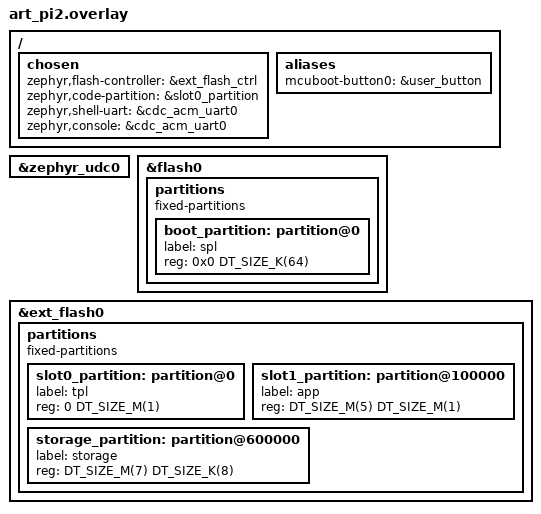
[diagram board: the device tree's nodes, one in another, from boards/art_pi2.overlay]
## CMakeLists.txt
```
# SPDX-License-Identifier: Apache-2.0

cmake_minimum_required(VERSION 3.20.0)

find_package(Zephyr REQUIRED HINTS $ENV{ZEPHYR_BASE})
project(tpl)

# ========================================
# TPL 固件头配置
# ========================================
target_compile_definitions(app PRIVATE
    FW_MAGIC_VALUE=FW_MAGIC_TPL
    FW_LOAD_ADDR=0x70000000
    FW_VERSION_VALUE=0x00010000     # v1.0.0
)

# ========================================
# 源文件
# ========================================
target_sources(app PRIVATE
    src/main.c
    src/fastboot_ops.c
    src/menu.c
    src/update_spl.c
    src/update_tpl.c
    src/update_app.c
    src/flash_helper.c
    ../common/ymodem.c
    ../common/firmware_loader.c
    ../common/fw_header.c
)

# ========================================
# 包含路径
# ========================================
zephyr_include_directories(app PRIVATE_HEADER ../common)

# ========================================
# 固件头链接脚本
# ========================================
# SORT_KEY "#fw_header" 确保固件头在 rom_start_address 之后、fill_with_zeros 之前
# ASCII 排序: "!" < "#fw_header" < "$" < "0x0" < "0x0vectors"
# 这样固件头位于地址 0x0-0x7F，填充到 0x400，向量表在 0x400
zephyr_linker_sources(ROM_START SORT_KEY "#fw_header" ../linker/fw_header.ld)

# ========================================
# 编译后处理：修正固件头 + 打印摘要
# 使用 add_custom_target + add_dependencies 确保在 zephyr_final 之后执行
# ========================================
set(FW_PATCH_SCRIPT "${CMAKE_SOURCE_DIR}/../tools/fw_patch.py")
set(FW_SUMMARY_SCRIPT "${CMAKE_SOURCE_DIR}/../tools/fw_summary.py")
set(ZEPHYR_BIN "${CMAKE_BINARY_DIR}/zephyr/zephyr.bin")

add_custom_target(tpl_patch_fw ALL
    COMMAND ${CMAKE_COMMAND} -E echo ""
    COMMAND ${CMAKE_COMMAND} -E echo "========================================"
    COMMAND ${CMAKE_COMMAND} -E echo "  Patching TPL firmware header..."
    COMMAND ${CMAKE_COMMAND} -E echo "========================================"
    COMMAND python3 ${FW_PATCH_SCRIPT} --vector-offset 0x400 ${ZEPHYR_BIN}
    COMMAND ${CMAKE_COMMAND} -E echo ""
    COMMAND python3 ${FW_SUMMARY_SCRIPT} ${ZEPHYR_BIN}
    COMMENT "Patching TPL firmware header and printing summary"
)

# 依赖 zephyr_final 目标（在 Zephyr 子目录中定义）
# CMake 允许跨目录的 add_dependencies
add_dependencies(tpl_patch_fw zephyr_final)
```

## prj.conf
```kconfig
CONFIG_MAIN_STACK_SIZE=4096
CONFIG_HEAP_MEM_POOL_SIZE=65536

CONFIG_STDOUT_CONSOLE=y

CONFIG_SERIAL=y
CONFIG_UART_STM32=y
CONFIG_UART_CONSOLE=y
CONFIG_GPIO=y
CONFIG_FLASH=y
CONFIG_FLASH_PAGE_LAYOUT=y
CONFIG_FLASH_STM32_XSPI=y
CONFIG_STM32_MEMMAP=y
CONFIG_USE_DT_CODE_PARTITION=y
CONFIG_FLASH_BASE_ADDRESS=0x70000000

CONFIG_LOG=y

# 使用内存缓冲日志，避免串口输出延迟影响 USB 枚举时序
CONFIG_LOG_MODE_DEFERRED=y
CONFIG_LOG_PROCESS_THREAD=y
CONFIG_LOG_PROCESS_THREAD_STACK_SIZE=1024
CONFIG_LOG_BUFFER_SIZE=65536
CONFIG_LOG_PRINTK=y
CONFIG_SHELL=y
CONFIG_CRC=y
CONFIG_REBOOT=y
CONFIG_BOOTLOADER_MCUBOOT=y
CONFIG_USB_DEVICE_STACK_NEXT=y
CONFIG_USBD_CDC_ACM_CLASS=y
CONFIG_USBD_FASTBOOT_CLASS=y
CONFIG_USBD_FASTBOOT_DOWNLOAD_BUF_SIZE=32768
CONFIG_USBD_FASTBOOTD=y
# CONFIG_UDC_STM32_CLOCK_CHECK is not set

# Increase UDC buffer pool to prevent buffer exhaustion
CONFIG_UDC_BUF_COUNT=32
CONFIG_UDC_BUF_POOL_SIZE=2048

# Increase UDC STM32 message queue size to prevent message loss
# during interrupt bursts (e.g., TXFE storm on short packet echo)
CONFIG_UDC_STM32_MAX_QMESSAGES=32

# Enable CDC ACM dedicated buffer pool
CONFIG_USBD_CDC_ACM_BUF_POOL=y

# Increase USB device core message queue size (default 10)
# Prevents event loss when multiple UDC events are queued rapidly
CONFIG_USBD_MAX_UDC_MSG=20

CONFIG_USBD_COMPOSITE_DEVICE=y

CONFIG_USBD_SHELL=y
```

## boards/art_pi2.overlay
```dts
/*
 * Copyright (c) 2024
 *
 * SPDX-License-Identifier: Apache-2.0
 */

/ {
    chosen {
        zephyr,flash-controller = &ext_flash_ctrl;
        zephyr,code-partition = &slot0_partition;
        zephyr,shell-uart = &cdc_acm_uart0;
        zephyr,console = &cdc_acm_uart0;
    };

    aliases {
        mcuboot-button0 = &user_button;
    };
};

&zephyr_udc0 {
    status = "okay";
};

&flash0 {
    partitions {
        compatible = "fixed-partitions";
        #address-cells = <1>;
        #size-cells = <1>;

        boot_partition: partition@0 {
            label = "spl";
            reg = <0x0 DT_SIZE_K(64)>;
        };
    };
};

&ext_flash0 {
    partitions {
        compatible = "fixed-partitions";
        #address-cells = <1>;
        #size-cells = <1>;

        /* 删除基础设备树中的 storage_partition */
        /delete-node/ partition@0;

        slot0_partition: partition@0 {
            label = "tpl";
            reg = <0 DT_SIZE_M(1)>;
        };

        slot1_partition: partition@100000 {
            label = "app";
            reg = <DT_SIZE_M(5) DT_SIZE_M(1)>;
        };

        storage_partition: partition@600000 {
            label = "storage";
            reg = <DT_SIZE_M(7) DT_SIZE_K(8)>;
        };
    };
};
```

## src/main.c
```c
/*
 * Copyright (c) 2024
 * SPDX-License-Identifier: Apache-2.0
 */

#include <zephyr/kernel.h>
#include <zephyr/sys/printk.h>
#include <zephyr/device.h>
#include <zephyr/devicetree.h>
#include <zephyr/drivers/gpio.h>
#include <cmsis_core.h>
#include "flash_helper.h"

#define RED_LED_NODE DT_NODELABEL(red_led)
#define BLUE_LED_NODE DT_NODELABEL(blue_led)
static const struct gpio_dt_spec red_led =
	GPIO_DT_SPEC_GET_OR(RED_LED_NODE, gpios, {0});
static const struct gpio_dt_spec blue_led =
	GPIO_DT_SPEC_GET_OR(BLUE_LED_NODE, gpios, {0});

int main(void)
{
	SCB_EnableICache();
	SCB_EnableDCache();

	if (device_is_ready(red_led.port)) {
		gpio_pin_configure_dt(&red_led, GPIO_OUTPUT);
	}
	if (device_is_ready(blue_led.port)) {
		gpio_pin_configure_dt(&blue_led, GPIO_OUTPUT);
	}

	flash_internal_init();
	flash_external_init();

	printk("TPL initialized\n");

	while (1) {
		k_sleep(K_MSEC(100));
	}
	return 0;
}
```

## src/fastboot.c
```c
/*
 * Copyright (c) 2024
 *
 * SPDX-License-Identifier: Apache-2.0
 */

/**
 * @file fastboot.c
 * @brief Fastboot protocol implementation for TPL bootloader
 */

#include "fastboot.h"
#include "flash_helper.h"
#include "firmware_loader.h"
#include "firmware_header.h"

#include <zephyr/kernel.h>
#include <zephyr/device.h>
#include <zephyr/usb/usbd.h>
#include <zephyr/logging/log.h>
#include <zephyr/sys/reboot.h>
#include <zephyr/sys/printk.h>
#include <string.h>
#include <stdlib.h>
#include <stdio.h>

LOG_MODULE_REGISTER(fastboot, CONFIG_LOG_DEFAULT_LEVEL);

/* ============================================================
 * USB Device Context & Descriptors
 * ============================================================ */

USBD_DEVICE_DEFINE(fastboot_usbd,
		   DEVICE_DT_GET(DT_NODELABEL(zephyr_udc0)),
		   FASTBOOT_VID, FASTBOOT_PID);

USBD_DESC_LANG_DEFINE(fastboot_lang);
USBD_DESC_MANUFACTURER_DEFINE(fastboot_mfr, "ART-Pi2");
USBD_DESC_PRODUCT_DEFINE(fastboot_product, "ART-Pi2 TPL Fastboot");

// USBD_DESC_CONFIG_DEFINE(fastboot_fs_cfg_desc, "Fastboot FS Config");
USBD_DESC_CONFIG_DEFINE(fastboot_hs_cfg_desc, "Fastboot HS Config");
// USBD_CONFIGURATION_DEFINE(fastboot_fs_config, 0, 250, &fastboot_fs_cfg_desc);
USBD_CONFIGURATION_DEFINE(fastboot_hs_config, 0, 250, &fastboot_hs_cfg_desc);

/* ============================================================
 * Fastboot Descriptors (must be in RAM, not flash)
 * ============================================================ */

/*
 * Descriptor template - used to init writable copies in RAM.
 * These are const and can stay in flash.
 */
#define FS_BULK_MPS USB_CONTROL_EP_MPS
#define HS_BULK_MPS 512

// static const struct usb_if_descriptor fastboot_fs_iface_tpl = {
// 	.bLength = sizeof(struct usb_if_descriptor),
// 	.bDescriptorType = USB_DESC_INTERFACE,
// 	.bInterfaceNumber = 0,
// 	.bAlternateSetting = 0,
// 	.bNumEndpoints = 2,
// 	.bInterfaceClass = FASTBOOT_IFACE_CLASS,
// 	.bInterfaceSubClass = FASTBOOT_IFACE_SUBCLASS,
// 	.bInterfaceProtocol = FASTBOOT_IFACE_PROTOCOL,
// 	.iInterface = 0,
// };

// static const struct usb_ep_descriptor fastboot_fs_bulk_out_tpl = {
// 	.bLength = sizeof(struct usb_ep_descriptor),
// 	.bDescriptorType = USB_DESC_ENDPOINT,
// 	.bEndpointAddress = FASTBOOT_BULK_OUT_EP,
// 	.bmAttributes = USB_EP_TYPE_BULK,
// 	.wMaxPacketSize = sys_cpu_to_le16(FS_BULK_MPS),
// 	.bInterval = 0x00,
// };

// static const struct usb_ep_descriptor fastboot_fs_bulk_in_tpl = {
// 	.bLength = sizeof(struct usb_ep_descriptor),
// 	.bDescriptorType = USB_DESC_ENDPOINT,
// 	.bEndpointAddress = FASTBOOT_BULK_IN_EP,
// 	.bmAttributes = USB_EP_TYPE_BULK,
// 	.wMaxPacketSize = sys_cpu_to_le16(FS_BULK_MPS),
// 	.bInterval = 0x00,
// };

static const struct usb_if_descriptor fastboot_hs_iface_tpl = {
	.bLength = sizeof(struct usb_if_descriptor),
	.bDescriptorType = USB_DESC_INTERFACE,
	.bInterfaceNumber = 0,
	.bAlternateSetting = 0,
	.bNumEndpoints = 2,
	.bInterfaceClass = FASTBOOT_IFACE_CLASS,
	.bInterfaceSubClass = FASTBOOT_IFACE_SUBCLASS,
	.bInterfaceProtocol = FASTBOOT_IFACE_PROTOCOL,
	.iInterface = 0,
};

static const struct usb_ep_descriptor fastboot_hs_bulk_out_tpl = {
	.bLength = sizeof(struct usb_ep_descriptor),
	.bDescriptorType = USB_DESC_ENDPOINT,
	.bEndpointAddress = FASTBOOT_BULK_OUT_EP,
	.bmAttributes = USB_EP_TYPE_BULK,
	.wMaxPacketSize = sys_cpu_to_le16(HS_BULK_MPS),
	.bInterval = 0x00,
};

static const struct usb_ep_descriptor fastboot_hs_bulk_in_tpl = {
	.bLength = sizeof(struct usb_ep_descriptor),
	.bDescriptorType = USB_DESC_ENDPOINT,
	.bEndpointAddress = FASTBOOT_BULK_IN_EP,
	.bmAttributes = USB_EP_TYPE_BULK,
	.wMaxPacketSize = sys_cpu_to_le16(HS_BULK_MPS),
	.bInterval = 0x00,
};

/* RAM copies of descriptors (BSS, in SRAM, writable) */
// static struct {
// 	struct usb_if_descriptor iface;
// 	struct usb_ep_descriptor bulk_out;
// 	struct usb_ep_descriptor bulk_in;
// 	struct usb_desc_header *desc_array[4];
// } fastboot_fs_desc_ram;

static struct {
	struct usb_if_descriptor iface;
	struct usb_ep_descriptor bulk_out;
	struct usb_ep_descriptor bulk_in;
	struct usb_desc_header *desc_array[4];
} fastboot_hs_desc_ram;

/* Pointers for get_desc() to return */
static struct usb_desc_header **fastboot_fs_desc;
static struct usb_desc_header **fastboot_hs_desc;

/* ============================================================
 * Fastboot Context & Class API
 * ============================================================ */

/* Static download buffer allocated from heap on demand */
static struct fastboot_ctx fb_ctx = {
	.state = FASTBOOT_STATE_OFFLINE,
	.download_buf = NULL,
};

static struct usbd_class_data *fb_c_data;

/* Forward declarations */
static void fastboot_process_data(struct usbd_class_data *c_data,
				  const uint8_t *data, size_t len);

/* Forward declarations */
static void fastboot_process_data(struct usbd_class_data *c_data,
				  const uint8_t *data, size_t len);
static void fastboot_init_desc(void);

static void *fastboot_get_desc(struct usbd_class_data *const c_data,
			       const enum usbd_speed speed)
{
	ARG_UNUSED(c_data);

	/* Ensure RAM descriptor copies are initialized before first use */
	fastboot_init_desc();

	if (speed == USBD_SPEED_HS) {
		return (void *)fastboot_hs_desc;
	}
	return (void *)fastboot_fs_desc;
}

static int fastboot_request(struct usbd_class_data *const c_data,
			    struct net_buf *buf, int err)
{
	struct usbd_context *ctx = usbd_class_get_ctx(c_data);

	if (err != 0) {
		printk("fastboot: bulk err %d\n", err);
		usbd_ep_buf_free(ctx, buf);
		return err;
	}

	if (buf->len > 0) {
		fastboot_process_data(c_data, buf->data, buf->len);
	}

	usbd_ep_buf_free(ctx, buf);

	/* Re-submit bulk OUT */
	{
		struct net_buf *new_buf = usbd_ep_buf_alloc(c_data,
					FASTBOOT_BULK_OUT_EP, 64);
		if (new_buf) {
			usbd_ep_enqueue(c_data, new_buf);
		}
	}

	return 0;
}

static void fastboot_enable(struct usbd_class_data *const c_data)
{
	struct net_buf *buf;

	printk("fastboot: enabled\n");
	fb_c_data = c_data;
	fb_ctx.state = FASTBOOT_STATE_IDLE;

	buf = usbd_ep_buf_alloc(c_data, FASTBOOT_BULK_OUT_EP, 64);
	if (buf) {
		usbd_ep_enqueue(c_data, buf);
	}
}

static void fastboot_disable(struct usbd_class_data *const c_data)
{
	printk("fastboot: disabled\n");
	fb_c_data = NULL;
	fb_ctx.state = FASTBOOT_STATE_OFFLINE;
	usbd_ep_dequeue(usbd_class_get_ctx(c_data), FASTBOOT_BULK_OUT_EP);
	usbd_ep_dequeue(usbd_class_get_ctx(c_data), FASTBOOT_BULK_IN_EP);
}

static void fastboot_init_desc(void)
{
	static bool initialized;

	if (initialized) {
		return;
	}

	// memcpy(&fastboot_fs_desc_ram.iface, &fastboot_fs_iface_tpl,
	//        sizeof(fastboot_fs_desc_ram.iface));
	// memcpy(&fastboot_fs_desc_ram.bulk_out, &fastboot_fs_bulk_out_tpl,
	//        sizeof(fastboot_fs_desc_ram.bulk_out));
	// memcpy(&fastboot_fs_desc_ram.bulk_in, &fastboot_fs_bulk_in_tpl,
	//        sizeof(fastboot_fs_desc_ram.bulk_in));
	// fastboot_fs_desc_ram.desc_array[0] = (struct usb_desc_header *)&fastboot_fs_desc_ram.iface;
	// fastboot_fs_desc_ram.desc_array[1] = (struct usb_desc_header *)&fastboot_fs_desc_ram.bulk_out;
	// fastboot_fs_desc_ram.desc_array[2] = (struct usb_desc_header *)&fastboot_fs_desc_ram.bulk_in;
	// fastboot_fs_desc_ram.desc_array[3] = NULL;
	// fastboot_fs_desc = fastboot_fs_desc_ram.desc_array;

	memcpy(&fastboot_hs_desc_ram.iface, &fastboot_hs_iface_tpl,
	       sizeof(fastboot_hs_desc_ram.iface));
	memcpy(&fastboot_hs_desc_ram.bulk_out, &fastboot_hs_bulk_out_tpl,
	       sizeof(fastboot_hs_desc_ram.bulk_out));
	memcpy(&fastboot_hs_desc_ram.bulk_in, &fastboot_hs_bulk_in_tpl,
	       sizeof(fastboot_hs_desc_ram.bulk_in));
	fastboot_hs_desc_ram.desc_array[0] = (struct usb_desc_header *)&fastboot_hs_desc_ram.iface;
	fastboot_hs_desc_ram.desc_array[1] = (struct usb_desc_header *)&fastboot_hs_desc_ram.bulk_out;
	fastboot_hs_desc_ram.desc_array[2] = (struct usb_desc_header *)&fastboot_hs_desc_ram.bulk_in;
	fastboot_hs_desc_ram.desc_array[3] = NULL;
	fastboot_hs_desc = fastboot_hs_desc_ram.desc_array;

	initialized = true;
}

static int fastboot_init_class(struct usbd_class_data *const c_data)
{
	ARG_UNUSED(c_data);
	memset(&fb_ctx, 0, sizeof(fb_ctx));
	fb_ctx.state = FASTBOOT_STATE_OFFLINE;
	printk("fastboot: class init\n");
	return 0;
}

static const struct usbd_class_api fastboot_class_api = {
	.get_desc    = fastboot_get_desc,
	.request     = fastboot_request,
	.enable      = fastboot_enable,
	.disable     = fastboot_disable,
	.init        = fastboot_init_class,
};

USBD_DEFINE_CLASS(fastboot_class, &fastboot_class_api, &fb_ctx, NULL);

/* ============================================================
 * Fastboot Response Helpers
 * ============================================================ */

static int fastboot_send(struct usbd_class_data *c_data,
			 const char *data, size_t len)
{
	struct net_buf *buf;
	if (!c_data) return -ENODEV;
	buf = usbd_ep_buf_alloc(c_data, FASTBOOT_BULK_IN_EP, len);
	if (!buf) return -ENOMEM;
	net_buf_add_mem(buf, data, len);
	return usbd_ep_enqueue(c_data, buf);
}

#define fastboot_okay(c)    fastboot_send((c), "OKAY", 4)
#define fastboot_fail(c,m)  do { \
	char _b[64]; int _n = snprintf(_b, sizeof(_b), "FAIL%s", (m)); \
	fastboot_send((c), _b, _n); } while(0)

/* ============================================================
 * Partition Table
 * ============================================================ */

struct fastboot_part {
	const char *name;
	uint32_t addr;
	uint32_t size;
	uint32_t magic;
	bool internal;
};

static const struct fastboot_part parts[] = {
	{"spl", FLASH_BASE_ADDR, SPL_FLASH_SIZE, FW_MAGIC_SPL, true},
	{"tpl", EXT_FLASH_SLOT0_ADDR, EXT_FLASH_SLOT0_SIZE, FW_MAGIC_TPL, false},
	{"app", EXT_FLASH_SLOT1_ADDR, EXT_FLASH_SLOT1_SIZE, FW_MAGIC_APP, false},
};

static const struct fastboot_part *find_part(const char *name)
{
	for (size_t i = 0; i < ARRAY_SIZE(parts); i++) {
		if (strcmp(parts[i].name, name) == 0) return &parts[i];
	}
	return NULL;
}

/* ============================================================
 * Command Handlers
 * ============================================================ */

static void cmd_getvar(struct usbd_class_data *c, const char *arg)
{
	char buf[64];

	if (strcmp(arg, "version") == 0) {
		fastboot_send(c, "OKAY0.4", 7);
	} else if (strcmp(arg, "board") == 0) {
		fastboot_send(c, "OKAYart-pi2", 12);
	} else if (strcmp(arg, "serial") == 0) {
		fastboot_send(c, "OKAY000000000000", 16);
	} else if (strcmp(arg, "max-download-size") == 0) {
		snprintf(buf, sizeof(buf), "OKAY0x%08x", FASTBOOT_DOWNLOAD_BUF);
		fastboot_send(c, buf, strlen(buf));
	} else if (strcmp(arg, "all") == 0) {
		fastboot_send(c, "INFOversion: 0.4", 16);
		fastboot_send(c, "INFOboard: art-pi2", 17);
		fastboot_send(c, "INFOserial: 000000000000", 22);
		fastboot_send(c, "INFOmax-download-size: 0x8000", 29);
		fastboot_okay(c);
	} else if (strncmp(arg, "partition-size:", 15) == 0) {
		const struct fastboot_part *p = find_part(arg + 15);
		if (p) {
			snprintf(buf, sizeof(buf), "OKAY0x%08x", p->size);
			fastboot_send(c, buf, strlen(buf));
		} else {
			fastboot_fail(c, "no such partition");
		}
	} else if (strncmp(arg, "partition-type:", 15) == 0) {
		const struct fastboot_part *p = find_part(arg + 15);
		if (p) {
			fastboot_send(c, "OKAYraw", 7);
		} else {
			fastboot_fail(c, "no such partition");
		}
	} else {
		fastboot_okay(c);
	}
}

static void cmd_download(struct usbd_class_data *c, const char *arg)
{
	uint32_t size = (uint32_t)strtoul(arg, NULL, 16);

	if (size == 0 || size > FASTBOOT_DOWNLOAD_BUF) {
		fastboot_fail(c, "bad size");
		return;
	}

	if (!fb_ctx.download_buf) {
		fb_ctx.download_buf = k_malloc(FASTBOOT_DOWNLOAD_BUF);
		if (!fb_ctx.download_buf) {
			fastboot_fail(c, "oom");
			return;
		}
	}

	fb_ctx.download_size = size;
	fb_ctx.download_received = 0;
	fb_ctx.state = FASTBOOT_STATE_DOWNLOAD;

	char resp[16];
	snprintf(resp, sizeof(resp), "DATA%08x", size);
	fastboot_send(c, resp, strlen(resp));
}

static void cmd_flash(struct usbd_class_data *c, const char *arg)
{
	const struct fastboot_part *p;
	int rc;

	if (fb_ctx.state != FASTBOOT_STATE_DOWNLOADED) {
		fastboot_fail(c, "no firmware downloaded");
		return;
	}

	p = find_part(arg);
	if (!p) {
		fastboot_fail(c, "no such partition");
		return;
	}

	if (fb_ctx.download_received < sizeof(struct firmware_header)) {
		fastboot_fail(c, "firmware too small");
		return;
	}

	/* Verify header */
	struct firmware_header *hdr = (struct firmware_header *)fb_ctx.download_buf;
	if (firmware_header_verify(hdr, p->magic) != FW_LOADER_SUCCESS) {
		fastboot_fail(c, "bad firmware header");
		return;
	}

	printk("fastboot: erasing %s...\n", p->name);
	if (p->internal) {
		rc = flash_internal_erase(p->addr, p->size);
	} else {
		rc = flash_external_erase(p->addr, p->size);
	}
	if (rc) { fastboot_fail(c, "erase failed"); return; }

	printk("fastboot: writing %s...\n", p->name);
	{
		uint32_t off = 0;
		uint32_t left = fb_ctx.download_received;
		while (left > 0) {
			uint32_t chunk = MIN(left, 256);
			if (p->internal) {
				rc = flash_internal_write(p->addr + off,
					fb_ctx.download_buf + off, chunk);
			} else {
				rc = flash_external_write(p->addr + off,
					fb_ctx.download_buf + off, chunk);
			}
			if (rc) break;
			off += chunk;
			left -= chunk;
		}
	}
	if (rc) { fastboot_fail(c, "write failed"); return; }

	/* TPL: set update request flag */
	if (strcmp(arg, "tpl") == 0) {
		flash_set_update_request(UPDATE_REQ_TPL);
	}

	fb_ctx.state = FASTBOOT_STATE_IDLE;
	k_free(fb_ctx.download_buf);
	fb_ctx.download_buf = NULL;

	fastboot_okay(c);
}

static void cmd_erase(struct usbd_class_data *c, const char *arg)
{
	const struct fastboot_part *p = find_part(arg);
	if (!p) { fastboot_fail(c, "no such partition"); return; }

	int rc;
	if (p->internal) {
		rc = flash_internal_erase(p->addr, p->size);
	} else {
		rc = flash_external_erase(p->addr, p->size);
	}

	if (rc) { fastboot_fail(c, "erase failed"); }
	else    { fastboot_okay(c); }
}

/* ============================================================
 * Command Dispatcher
 * ============================================================ */

static void handle_cmd(struct usbd_class_data *c, const char *cmd)
{
	printk("fastboot: cmd '%s'\n", cmd);

	if (strncmp(cmd, "getvar:", 7) == 0)
		cmd_getvar(c, cmd + 7);
	else if (strncmp(cmd, "download:", 9) == 0)
		cmd_download(c, cmd + 9);
	else if (strncmp(cmd, "flash:", 6) == 0)
		cmd_flash(c, cmd + 6);
	else if (strncmp(cmd, "erase:", 6) == 0)
		cmd_erase(c, cmd + 6);
	else if (strcmp(cmd, "reboot") == 0) {
		fastboot_okay(c);
		k_sleep(K_MSEC(100));
		sys_reboot(SYS_REBOOT_COLD);
	} else if (strcmp(cmd, "continue") == 0)
		fastboot_okay(c);
	else
		fastboot_fail(c, "unknown command");
}

/* ============================================================
 * Data Processor
 * ============================================================ */

static void fastboot_process_data(struct usbd_class_data *c_data,
				  const uint8_t *data, size_t len)
{
	switch (fb_ctx.state) {

	case FASTBOOT_STATE_IDLE: {
		char cmd[64];
		size_t n = MIN(len, sizeof(cmd) - 1);
		memcpy(cmd, data, n);
		cmd[n] = '\0';
		while (n > 0 && (cmd[n-1] == '\r' || cmd[n-1] == '\n'))
			cmd[--n] = '\0';
		if (n > 0) handle_cmd(c_data, cmd);
		break;
	}

	case FASTBOOT_STATE_DOWNLOAD: {
		uint32_t copy = MIN(len,
			fb_ctx.download_size - fb_ctx.download_received);
		if (copy > 0) {
			memcpy(fb_ctx.download_buf + fb_ctx.download_received,
			       data, copy);
			fb_ctx.download_received += copy;
		}
		if (fb_ctx.download_received >= fb_ctx.download_size) {
			fb_ctx.state = FASTBOOT_STATE_DOWNLOADED;
			fastboot_okay(c_data);
		}
		break;
	}

	default:
		fastboot_fail(c_data, "protocol error");
		fb_ctx.state = FASTBOOT_STATE_IDLE;
		break;
	}
}

/* ============================================================
 * VBUS Message Callback
 * ============================================================ */

static void fb_msg_cb(struct usbd_context *const ctx,
		      const struct usbd_msg *msg)
{
	switch (msg->type) {
	case USBD_MSG_VBUS_READY:
		printk("fastboot: VBUS ready\n");
		usbd_enable(ctx);
		break;
	case USBD_MSG_VBUS_REMOVED:
		printk("fastboot: VBUS removed\n");
		usbd_disable(ctx);
		break;
	default:
		break;
	}
}

/* ============================================================
 * Public API
 * ============================================================ */

int fastboot_init(void)
{
	struct usbd_context *uds_ctx = &fastboot_usbd;
	int err;

	printk("fastboot: init start\n");

	err = usbd_add_descriptor(uds_ctx, &fastboot_lang);
	if (err) { printk("fastboot: lang fail %d\n", err); return err; }

	err = usbd_add_descriptor(uds_ctx, &fastboot_mfr);
	if (err) { printk("fastboot: mfr fail %d\n", err); return err; }

	err = usbd_add_descriptor(uds_ctx, &fastboot_product);
	if (err) { printk("fastboot: product fail %d\n", err); return err; }

	err = usbd_msg_register_cb(uds_ctx, fb_msg_cb);
	if (err) { printk("fastboot: msg cb fail %d\n", err); return err; }

	// err = usbd_add_configuration(uds_ctx, USBD_SPEED_FS,
	// 			     &fastboot_fs_config);
	// if (err) { printk("fastboot: FS cfg fail %d\n", err); return err; }

	err = usbd_add_configuration(uds_ctx, USBD_SPEED_HS,
				     &fastboot_hs_config);
	if (err) { printk("fastboot: HS cfg fail %d\n", err); return err; }

	// err = usbd_register_class(uds_ctx, "fastboot_class",
	// 			  USBD_SPEED_FS, 1);
	// if (err) { printk("fastboot: FS reg fail %d\n", err); return err; }

	err = usbd_register_class(uds_ctx, "fastboot_class",
				  USBD_SPEED_HS, 1);
	if (err) { printk("fastboot: HS reg fail %d\n", err); return err; }

	err = usbd_init(uds_ctx);
	if (err) { printk("fastboot: init fail %d\n", err); return err; }

	if (usbd_can_detect_vbus(uds_ctx)) {
		printk("fastboot: VBUS detect enabled, waiting for cable\n");
	} else {
		printk("fastboot: no VBUS detect, enabling directly\n");
		err = usbd_enable(uds_ctx);
		if (err) { printk("fastboot: enable fail %d\n", err); return err; }
	}

	printk("fastboot: USB ready\n");
	return 0;
}

void fastboot_poll(void)
{
	/* USB is interrupt-driven, nothing to poll */
}
```

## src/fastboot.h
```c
/*
 * Copyright (c) 2024
 *
 * SPDX-License-Identifier: Apache-2.0
 */

#ifndef FASTBOOT_H
#define FASTBOOT_H

/**
 * @file fastboot.h
 * @brief Fastboot protocol implementation for TPL bootloader
 *
 * Implements the Android Fastboot protocol for firmware updates via USB.
 * Uses Zephyr's new USB device stack (USB_DEVICE_STACK_NEXT).
 */

#include <zephyr/kernel.h>
#include <zephyr/types.h>
#include <stdbool.h>
#include <stddef.h>
#include <stdint.h>

/* ============================================================
 * Fastboot USB Device Identification
 * ============================================================ */

#define FASTBOOT_VID             0x2FE3  /* Zephyr Project VID */
#define FASTBOOT_PID             0x1001  /* TPL Fastboot PID */

/* ============================================================
 * Fastboot USB Interface Descriptor Values
 * ============================================================ */

#define FASTBOOT_IFACE_CLASS      0xFF
#define FASTBOOT_IFACE_SUBCLASS   0x42
#define FASTBOOT_IFACE_PROTOCOL   0x03

/* ============================================================
 * USB Endpoint Assignments
 * ============================================================ */

#define FASTBOOT_BULK_OUT_EP      0x01   /* EP1 OUT (host to device) */
#define FASTBOOT_BULK_IN_EP       0x81   /* EP1 IN  (device to host) */

/* ============================================================
 * Protocol Constants
 * ============================================================ */

#define FASTBOOT_MAX_CMDBUF       64
#define FASTBOOT_MAX_RSPBUF       64

/*
 * Download buffer size: 32KB.
 * SRAM0 (zephyr,sram) = 456KB but BSS/data/text share this space.
 * TPL itself plus USB stack takes significant RAM.
 * Start small for testing; increase once USB enumeration is verified.
 */
#define FASTBOOT_DOWNLOAD_BUF     (32 * 1024)

/* Fastboot response prefixes */
#define FASTBOOT_RSP_OKAY         "OKAY"
#define FASTBOOT_RSP_FAIL         "FAIL"
#define FASTBOOT_RSP_DATA         "DATA"
#define FASTBOOT_RSP_INFO         "INFO"

/* ============================================================
 * Fastboot State Machine
 * ============================================================ */

enum fastboot_state {
	FASTBOOT_STATE_OFFLINE,      /* USB not yet enabled */
	FASTBOOT_STATE_IDLE,         /* Waiting for commands */
	FASTBOOT_STATE_DOWNLOAD,     /* Receiving firmware data */
	FASTBOOT_STATE_DOWNLOADED,   /* Firmware ready, waiting for flash/cmd */
	FASTBOOT_STATE_ERROR,        /* Error, need to recover */
};

/* ============================================================
 * Fastboot Context
 * ============================================================ */

struct fastboot_ctx {
	enum fastboot_state state;
	uint8_t *download_buf;
	uint32_t download_size;
	uint32_t download_received;
};

/* ============================================================
 * Public API
 * ============================================================ */

/**
 * @brief Initialize Fastboot USB device
 *
 * @return 0 on success, negative errno on failure
 */
int fastboot_init(void);

/**
 * @brief Fastboot poll function (for main loop)
 */
void fastboot_poll(void);

#endif /* FASTBOOT_H */
```

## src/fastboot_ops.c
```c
/*
 * Copyright (c) 2024
 *
 * SPDX-License-Identifier: Apache-2.0
 */

/**
 * @file fastboot_ops.c
 * @brief Fastboot Ops and partition registration (SYS_INIT)
 *
 * Runs before usbd_fastbootd init to register partitions and
 * flash operations before USB is initialized.
 */

#include <zephyr/init.h>
#include <zephyr/kernel.h>
#include <zephyr/devicetree.h>
#include <zephyr/usb/class/usbd_fastboot.h>

#include "flash_helper.h"
#include "firmware_header.h"

/* ============================================================
 * Partition Table (from DTS)
 * ============================================================ */

static const struct fastboot_part fb_parts[] = {
	FASTBOOT_PART_DEFINE(DT_NODELABEL(boot_partition),  FW_MAGIC_SPL, true),
	FASTBOOT_PART_DEFINE(DT_NODELABEL(slot0_partition), FW_MAGIC_TPL, false),
	FASTBOOT_PART_DEFINE(DT_NODELABEL(slot1_partition), FW_MAGIC_APP, false),
};

/* ============================================================
 * Ops
 * ============================================================ */

static int fb_flash_erase(uint32_t addr, uint32_t size)
{
	if (addr >= 0x08000000 && addr < 0x08100000) {
		return flash_internal_erase(addr, size);
	}
	return flash_external_erase(addr, size);
}

static int fb_flash_write(uint32_t addr, const uint8_t *data, uint32_t size)
{
	if (addr >= 0x08000000 && addr < 0x08100000) {
		return flash_internal_write(addr, data, size);
	}
	return flash_external_write(addr, data, size);
}

static int fb_firmware_verify(const uint8_t *data, uint32_t size,
			      uint32_t expected_magic)
{
	if (size < sizeof(struct firmware_header)) {
		return -EINVAL;
	}
	const struct firmware_header *hdr =
		(const struct firmware_header *)data;

	return (hdr->magic == expected_magic) ? 0 : -EINVAL;
}

static struct fastboot_ops fb_ops = {
	.flash_erase     = fb_flash_erase,
	.flash_write     = fb_flash_write,
	.firmware_verify = fb_firmware_verify,
};

/* ============================================================
 * SYS_INIT: runs before usbd_fastbootd
 * ============================================================ */

static int fastboot_ops_init(void)
{
	fastboot_register_partitions(fb_parts, ARRAY_SIZE(fb_parts));
	fastboot_register_ops(&fb_ops);
	return 0;
}

SYS_INIT(fastboot_ops_init, APPLICATION, CONFIG_APPLICATION_INIT_PRIORITY);
```

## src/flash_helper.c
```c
/*
 * Copyright (c) 2024
 *
 * SPDX-License-Identifier: Apache-2.0
 */

#include "flash_helper.h"
#include <zephyr/sys/printk.h>
#include <string.h>

/* Flash 设备指针 */
static const struct device *flash_internal_dev = NULL;
static const struct device *flash_external_dev = NULL;

/* CRC16 表 (多项式: 0x1021) */
static const uint16_t crc16_table[256] = {
    0x0000, 0x1021, 0x2042, 0x3063, 0x4084, 0x50A5, 0x60C6, 0x70E7,
    0x8108, 0x9129, 0xA14A, 0xB16B, 0xC18C, 0xD1AD, 0xE1CE, 0xF1EF,
    0x1231, 0x0210, 0x3273, 0x2252, 0x52B5, 0x4294, 0x72F7, 0x62D6,
    0x9339, 0x8318, 0xB37B, 0xA35A, 0xD3BD, 0xC39C, 0xF3FF, 0xE3DE,
    0x2462, 0x3443, 0x0420, 0x1401, 0x64E6, 0x74C7, 0x44A4, 0x5485,
    0xA56A, 0xB54B, 0x8528, 0x9509, 0xE5EE, 0xF5CF, 0xC5AC, 0xD58D,
    0x3653, 0x2672, 0x1611, 0x0630, 0x76D7, 0x66F6, 0x5695, 0x46B4,
    0xB75B, 0xA77A, 0x9719, 0x8738, 0xF7DF, 0xE7FE, 0xD79D, 0xC7BC,
    0x48C4, 0x58E5, 0x6886, 0x78A7, 0x0840, 0x1861, 0x2802, 0x3823,
    0xC9CC, 0xD9ED, 0xE98E, 0xF9AF, 0x8948, 0x9969, 0xA90A, 0xB92B,
    0x5AF5, 0x4AD4, 0x7AB7, 0x6A96, 0x1A71, 0x0A50, 0x3A33, 0x2A12,
    0xDBFD, 0xCBDC, 0xFBBF, 0xEB9E, 0x9B79, 0x8B58, 0xBB3B, 0xAB1A,
    0x6CA6, 0x7C87, 0x4CE4, 0x5CC5, 0x2C22, 0x3C03, 0x0C60, 0x1C41,
    0xEDAE, 0xFD8F, 0xCDEC, 0xDDCD, 0xAD2A, 0xBD0B, 0x8D68, 0x9D49,
    0x7E97, 0x6EB6, 0x5ED5, 0x4EF4, 0x3E13, 0x2E32, 0x1E51, 0x0E70,
    0xFF9F, 0xEFBE, 0xDFDD, 0xCFFC, 0xBF1B, 0xAF3A, 0x9F59, 0x8F78,
    0x9188, 0x81A9, 0xB1CA, 0xA1EB, 0xD10C, 0xC12D, 0xF14E, 0xE16F,
    0x1080, 0x00A1, 0x30C2, 0x20E3, 0x5004, 0x4025, 0x7046, 0x6067,
    0x83B9, 0x9398, 0xA3FB, 0xB3DA, 0xC33D, 0xD31C, 0xE37F, 0xF35E,
    0x02B1, 0x1290, 0x22F3, 0x32D2, 0x4235, 0x5214, 0x6277, 0x7256,
    0xB5EA, 0xA5CB, 0x95A8, 0x8589, 0xF56E, 0xE54F, 0xD52C, 0xC50D,
    0x34E2, 0x24C3, 0x14A0, 0x0481, 0x7466, 0x6447, 0x5424, 0x4405,
    0xA7DB, 0xB7FA, 0x8799, 0x97B8, 0xE75F, 0xF77E, 0xC71D, 0xD73C,
    0x26D3, 0x36F2, 0x0691, 0x16B0, 0x6657, 0x7676, 0x4615, 0x5634,
    0xD94C, 0xC96D, 0xF90E, 0xE92F, 0x99C8, 0x89E9, 0xB98A, 0xA9AB,
    0x5844, 0x4865, 0x7806, 0x6827, 0x18C0, 0x08E1, 0x3882, 0x28A3,
    0xCB7D, 0xDB5C, 0xEB3F, 0xFB1E, 0x8BF9, 0x9BD8, 0xABBB, 0xBB9A,
    0x4A75, 0x5A54, 0x6A37, 0x7A16, 0x0AF1, 0x1AD0, 0x2AB3, 0x3A92,
    0xFD2E, 0xED0F, 0xDD6C, 0xCD4D, 0xBDAA, 0xAD8B, 0x9DE8, 0x8DC9,
    0x7C26, 0x6C07, 0x5C64, 0x4C45, 0x3CA2, 0x2C83, 0x1CE0, 0x0CC1,
    0xEF1F, 0xFF3E, 0xCF5D, 0xDF7C, 0xAF9B, 0xBFBA, 0x8FD9, 0x9FF8,
    0x6E17, 0x7E36, 0x4E55, 0x5E74, 0x2E93, 0x3EB2, 0x0ED1, 0x1EF0
};

int flash_internal_init(void)
{
    flash_internal_dev = DEVICE_DT_GET(DT_NODELABEL(flash));

    if (!device_is_ready(flash_internal_dev)) {
        printk("Error: Internal flash device not ready\n");
        return FLASH_OP_ERROR;
    }

    return FLASH_OP_SUCCESS;
}

int flash_external_init(void)
{
    flash_external_dev = DEVICE_DT_GET(DT_NODELABEL(ext_flash_ctrl));

    if (!device_is_ready(flash_external_dev)) {
        printk("Error: External flash device not ready\n");
        return FLASH_OP_ERROR;
    }

    return FLASH_OP_SUCCESS;
}

int flash_internal_erase(uint32_t addr, size_t len)
{
    struct flash_pages_info page_info;
    off_t offset;
    int rc;

    if (flash_internal_dev == NULL) {
        if (flash_internal_init() != FLASH_OP_SUCCESS) {
            return FLASH_OP_ERROR;
        }
    }

    if (addr < FLASH_BASE_ADDR || (addr + len) > (FLASH_BASE_ADDR + SPL_FLASH_SIZE)) {
        printk("Error: Invalid internal flash address range\n");
        return FLASH_OP_ERROR;
    }

    offset = addr - FLASH_BASE_ADDR;

    rc = flash_get_page_info_by_offs(flash_internal_dev, offset, &page_info);
    if (rc != 0) {
        printk("Error: Failed to get page info\n");
        return FLASH_OP_ERROR;
    }

    rc = flash_erase(flash_internal_dev, page_info.start_offset, page_info.size);
    if (rc != 0) {
        printk("Error: Flash erase failed (rc=%d)\n", rc);
        return FLASH_OP_ERROR;
    }

    return FLASH_OP_SUCCESS;
}

int flash_internal_write(uint32_t addr, const uint8_t *data, size_t len)
{
    off_t offset;
    int rc;

    if (flash_internal_dev == NULL) {
        if (flash_internal_init() != FLASH_OP_SUCCESS) {
            return FLASH_OP_ERROR;
        }
    }

    if (addr < FLASH_BASE_ADDR || (addr + len) > (FLASH_BASE_ADDR + SPL_FLASH_SIZE)) {
        printk("Error: Invalid internal flash address range\n");
        return FLASH_OP_ERROR;
    }

    if ((addr & 0x3) != 0) {
        printk("Error: Flash write address must be 4-byte aligned\n");
        return FLASH_OP_ERROR;
    }

    offset = addr - FLASH_BASE_ADDR;

    rc = flash_write(flash_internal_dev, offset, data, len);
    if (rc != 0) {
        printk("Error: Flash write failed (rc=%d)\n", rc);
        return FLASH_OP_ERROR;
    }

    return FLASH_OP_SUCCESS;
}

int flash_internal_read(uint32_t addr, uint8_t *data, size_t len)
{
    off_t offset;
    int rc;

    if (flash_internal_dev == NULL) {
        if (flash_internal_init() != FLASH_OP_SUCCESS) {
            return FLASH_OP_ERROR;
        }
    }

    if (addr < FLASH_BASE_ADDR || (addr + len) > (FLASH_BASE_ADDR + SPL_FLASH_SIZE)) {
        printk("Error: Invalid internal flash address range\n");
        return FLASH_OP_ERROR;
    }

    offset = addr - FLASH_BASE_ADDR;

    rc = flash_read(flash_internal_dev, offset, data, len);
    if (rc != 0) {
        printk("Error: Flash read failed (rc=%d)\n", rc);
        return FLASH_OP_ERROR;
    }

    return FLASH_OP_SUCCESS;
}

int flash_external_erase(uint32_t addr, size_t len)
{
    struct flash_pages_info page_info;
    off_t offset;
    int rc;

    if (flash_external_dev == NULL) {
        if (flash_external_init() != FLASH_OP_SUCCESS) {
            return FLASH_OP_ERROR;
        }
    }

    offset = addr - EXT_FLASH_BASE_ADDR;

    rc = flash_get_page_info_by_offs(flash_external_dev, offset, &page_info);
    if (rc != 0) {
        printk("Error: Failed to get page info\n");
        return FLASH_OP_ERROR;
    }

    rc = flash_erase(flash_external_dev, page_info.start_offset, page_info.size);
    if (rc != 0) {
        printk("Error: External flash erase failed (rc=%d)\n", rc);
        return FLASH_OP_ERROR;
    }

    return FLASH_OP_SUCCESS;
}

int flash_external_write(uint32_t addr, const uint8_t *data, size_t len)
{
    off_t offset;
    int rc;

    if (flash_external_dev == NULL) {
        if (flash_external_init() != FLASH_OP_SUCCESS) {
            return FLASH_OP_ERROR;
        }
    }

    if ((addr & 0x3) != 0) {
        printk("Error: Flash write address must be 4-byte aligned\n");
        return FLASH_OP_ERROR;
    }

    offset = addr - EXT_FLASH_BASE_ADDR;

    rc = flash_write(flash_external_dev, offset, data, len);
    if (rc != 0) {
        printk("Error: External flash write failed (rc=%d)\n", rc);
        return FLASH_OP_ERROR;
    }

    return FLASH_OP_SUCCESS;
}

int flash_external_read(uint32_t addr, uint8_t *data, size_t len)
{
    off_t offset;
    int rc;

    if (flash_external_dev == NULL) {
        if (flash_external_init() != FLASH_OP_SUCCESS) {
            return FLASH_OP_ERROR;
        }
    }

    offset = addr - EXT_FLASH_BASE_ADDR;

    rc = flash_read(flash_external_dev, offset, data, len);
    if (rc != 0) {
        printk("Error: External flash read failed (rc=%d)\n", rc);
        return FLASH_OP_ERROR;
    }

    return FLASH_OP_SUCCESS;
}

bool flash_verify_magic(uint32_t addr, uint32_t magic)
{
    uint32_t *ptr = (uint32_t *)addr;

    if ((addr & 0x3) != 0) {
        return false;
    }

    return (*ptr == magic);
}

uint16_t flash_calc_crc16(const uint8_t *data, size_t len)
{
    uint16_t crc = 0xFFFF;

    while (len--) {
        crc = (crc << 8) ^ crc16_table[((crc >> 8) ^ *data++) & 0xFF];
    }

    return crc;
}

bool flash_verify_crc(uint32_t addr, size_t len, uint16_t expected_crc)
{
    uint16_t calc_crc;
    const uint8_t *data = (const uint8_t *)addr;

    calc_crc = flash_calc_crc16(data, len);

    return (calc_crc == expected_crc);
}

int flash_copy_ext_to_int(uint32_t dst_addr, uint32_t src_addr, size_t len)
{
    uint8_t *src_ptr;
    int rc;

    /* 源地址在外部 Flash Memory Map 区域，可以直接读取 */
    src_ptr = (uint8_t *)src_addr;

    /* 按页写入内部 Flash */
    size_t offset = 0;
    while (offset < len) {
        size_t write_len = (len - offset > 256) ? 256 : (len - offset);

        rc = flash_internal_write(dst_addr + offset, src_ptr + offset, write_len);
        if (rc != 0) {
            printk("Error: Copy ext to int failed at offset 0x%x\n", offset);
            return FLASH_OP_ERROR;
        }

        offset += write_len;
    }

    return FLASH_OP_SUCCESS;
}

int flash_copy_ext_to_ext(uint32_t dst_addr, uint32_t src_addr, size_t len)
{
    uint8_t *src_ptr;
    int rc;

    /* 源地址在外部 Flash Memory Map 区域，可以直接读取 */
    src_ptr = (uint8_t *)src_addr;

    /* 按页写入外部 Flash */
    size_t offset = 0;
    while (offset < len) {
        size_t write_len = (len - offset > 256) ? 256 : (len - offset);

        rc = flash_external_write(dst_addr + offset, src_ptr + offset, write_len);
        if (rc != 0) {
            printk("Error: Copy ext to ext failed at offset 0x%x\n", offset);
            return FLASH_OP_ERROR;
        }

        offset += write_len;
    }

    return FLASH_OP_SUCCESS;
}

int flash_storage_write(uint32_t offset, const uint8_t *data, size_t len)
{
    uint32_t addr = EXT_FLASH_STORAGE_ADDR + offset;

    if (offset + len > EXT_FLASH_STORAGE_SIZE) {
        printk("Error: Storage write out of bounds\n");
        return FLASH_OP_ERROR;
    }

    return flash_external_write(addr, data, len);
}

int flash_storage_read(uint32_t offset, uint8_t *data, size_t len)
{
    uint32_t addr = EXT_FLASH_STORAGE_ADDR + offset;

    if (offset + len > EXT_FLASH_STORAGE_SIZE) {
        printk("Error: Storage read out of bounds\n");
        return FLASH_OP_ERROR;
    }

    return flash_external_read(addr, data, len);
}

int flash_set_update_request(uint32_t req)
{
    return flash_storage_write(STORAGE_OFFSET_UPDATE_REQ,
                               (const uint8_t *)&req, sizeof(req));
}

uint32_t flash_get_update_request(void)
{
    uint32_t req = UPDATE_REQ_NONE;

    flash_storage_read(STORAGE_OFFSET_UPDATE_REQ,
                       (uint8_t *)&req, sizeof(req));

    return req;
}

int flash_clear_update_request(void)
{
    uint32_t none = UPDATE_REQ_NONE;
    return flash_storage_write(STORAGE_OFFSET_UPDATE_REQ,
                               (const uint8_t *)&none, sizeof(none));
}
```

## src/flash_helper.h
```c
/*
 * Copyright (c) 2024
 *
 * SPDX-License-Identifier: Apache-2.0
 */

#ifndef TPL_FLASH_HELPER_H
#define TPL_FLASH_HELPER_H

#include <zephyr/kernel.h>
#include <zephyr/device.h>
#include <zephyr/devicetree.h>
#include <zephyr/drivers/flash.h>
#include <zephyr/storage/flash_map.h>
#include <stdbool.h>
#include <stddef.h>
#include <stdint.h>

/* Flash 地址定义 */
#define FLASH_BASE_ADDR            0x08000000
#define SPL_FLASH_SIZE             (64 * 1024)  /* 64KB 内部 Flash */

#define EXT_FLASH_BASE_ADDR        0x70000000

/* slot0: TPL (外部 Flash offset 0x000000, 1MB) */
#define EXT_FLASH_TPL_ADDR         0x70000000
#define EXT_FLASH_TPL_SIZE         (1 * 1024 * 1024) /* 1MB */
#define EXT_FLASH_SLOT0_ADDR       0x70000000
#define EXT_FLASH_SLOT0_SIZE       (1 * 1024 * 1024) /* 1MB */

/* slot1: APP (外部 Flash offset 0x100000, 1MB) */
#define EXT_FLASH_SLOT1_ADDR       0x70100000
#define EXT_FLASH_SLOT1_SIZE       (1 * 1024 * 1024) /* 1MB */

/* storage (外部 Flash offset 0x600000, 8KB) */
#define EXT_FLASH_STORAGE_ADDR     0x70600000
#define EXT_FLASH_STORAGE_SIZE     (8 * 1024)    /* 8KB */

/* Magic Number 定义 */
#define SPL_MAGIC                  0x53504C53  /* "SPLS" */
#define TPL_MAGIC                  0x54504C54  /* "TPLT" */
#define APP_MAGIC                  0x41505041  /* "APPA" */

/* Flash 操作结果 */
#define FLASH_OP_SUCCESS           0
#define FLASH_OP_ERROR             -1
#define FLASH_OP_VERIFY_ERROR      -2
#define FLASH_OP_TIMEOUT           -3

/* Storage 区域偏移和大小 */
#define STORAGE_OFFSET_UPDATE_REQ  0   /* 升级请求标志 (4字节) */
#define STORAGE_OFFSET_BOOT_COUNT  4   /* 启动计数 (4字节) */
#define STORAGE_SIZE_UPDATE_REQ    4
#define STORAGE_SIZE_BOOT_COUNT    4

/* 升级请求标志值 */
#define UPDATE_REQ_NONE            0x00000000  /* 无升级请求 */
#define UPDATE_REQ_APP             0x41505251  /* "APRQ" - 应用升级请求 */
#define UPDATE_REQ_TPL             0x54505251  /* "TPRQ" - TPL 升级请求 */

/**
 * @brief 初始化内部 Flash
 * @return 0 成功，负数失败
 */
int flash_internal_init(void);

/**
 * @brief 初始化外部 Flash
 * @return 0 成功，负数失败
 */
int flash_external_init(void);

/**
 * @brief 擦除内部 Flash 区域
 * @param addr 起始地址
 * @param len 长度
 * @return 0 成功，负数失败
 */
int flash_internal_erase(uint32_t addr, size_t len);

/**
 * @brief 写入内部 Flash
 * @param addr 起始地址
 * @param data 数据指针
 * @param len 长度
 * @return 0 成功，负数失败
 */
int flash_internal_write(uint32_t addr, const uint8_t *data, size_t len);

/**
 * @brief 读取内部 Flash
 * @param addr 起始地址
 * @param data 数据缓冲区
 * @param len 长度
 * @return 0 成功，负数失败
 */
int flash_internal_read(uint32_t addr, uint8_t *data, size_t len);

/**
 * @brief 擦除外部 Flash 区域
 * @param addr 起始地址
 * @param len 长度
 * @return 0 成功，负数失败
 */
int flash_external_erase(uint32_t addr, size_t len);

/**
 * @brief 写入外部 Flash
 * @param addr 起始地址
 * @param data 数据指针
 * @param len 长度
 * @return 0 成功，负数失败
 */
int flash_external_write(uint32_t addr, const uint8_t *data, size_t len);

/**
 * @brief 读取外部 Flash
 * @param addr 起始地址
 * @param data 数据缓冲区
 * @param len 长度
 * @return 0 成功，负数失败
 */
int flash_external_read(uint32_t addr, uint8_t *data, size_t len);

/**
 * @brief 验证 Flash 区域的 Magic Number
 * @param addr 地址
 * @param magic 期望的 Magic Number
 * @return true 匹配，false 不匹配
 */
bool flash_verify_magic(uint32_t addr, uint32_t magic);

/**
 * @brief 计算 CRC16 校验
 * @param data 数据指针
 * @param len 长度
 * @return CRC16 值
 */
uint16_t flash_calc_crc16(const uint8_t *data, size_t len);

/**
 * @brief 验证 Flash 区域的 CRC
 * @param addr 地址
 * @param len 长度
 * @param expected_crc 期望的 CRC 值
 * @return true 匹配，false 不匹配
 */
bool flash_verify_crc(uint32_t addr, size_t len, uint16_t expected_crc);

/**
 * @brief 从外部 Flash 复制数据到内部 Flash
 * @param dst_addr 目标内部 Flash 地址
 * @param src_addr 源外部 Flash 地址
 * @param len 长度
 * @return 0 成功，负数失败
 */
int flash_copy_ext_to_int(uint32_t dst_addr, uint32_t src_addr, size_t len);

/**
 * @brief 从外部 Flash 复制数据到外部 Flash
 * @param dst_addr 目标外部 Flash 地址
 * @param src_addr 源外部 Flash 地址
 * @param len 长度
 * @return 0 成功，负数失败
 */
int flash_copy_ext_to_ext(uint32_t dst_addr, uint32_t src_addr, size_t len);

/**
 * @brief 写入 Storage 区域
 * @param offset Storage 内偏移
 * @param data 数据指针
 * @param len 长度
 * @return 0 成功，负数失败
 */
int flash_storage_write(uint32_t offset, const uint8_t *data, size_t len);

/**
 * @brief 读取 Storage 区域
 * @param offset Storage 内偏移
 * @param data 数据缓冲区
 * @param len 长度
 * @return 0 成功，负数失败
 */
int flash_storage_read(uint32_t offset, uint8_t *data, size_t len);

/**
 * @brief 设置升级请求标志
 * @param req 升级请求值 (UPDATE_REQ_APP / UPDATE_REQ_TPL / UPDATE_REQ_NONE)
 * @return 0 成功，负数失败
 */
int flash_set_update_request(uint32_t req);

/**
 * @brief 获取升级请求标志
 * @return 升级请求值
 */
uint32_t flash_get_update_request(void);

/**
 * @brief 清除升级请求标志
 * @return 0 成功，负数失败
 */
int flash_clear_update_request(void);

#endif /* TPL_FLASH_HELPER_H */
```

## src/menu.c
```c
/*
 * Copyright (c) 2024
 *
 * SPDX-License-Identifier: Apache-2.0
 */

#include "menu.h"
#include "flash_helper.h"
#include <zephyr/kernel.h>
#include <zephyr/sys/printk.h>
#include <zephyr/drivers/uart.h>
#include <zephyr/device.h>
#include <zephyr/devicetree.h>
#include <stdarg.h>
#include <stdio.h>

/* UART 设备 */
static const struct device *menu_uart_dev = NULL;

/* UART 初始化 */
static void menu_uart_init(void)
{
    if (menu_uart_dev == NULL) {
        menu_uart_dev = DEVICE_DT_GET(DT_CHOSEN(zephyr_console));
        if (!device_is_ready(menu_uart_dev)) {
            printk("Error: UART device not ready\n");
        }
    }
}

int menu_getchar(void)
{
    uint8_t c;

    menu_uart_init();

    if (menu_uart_dev == NULL) {
        return -1;
    }

    /* 使用 uart_poll_in 替代 uart_fifo_read
     * 原因：YModem 协议也使用 uart_poll_in，两者共用 UART 时
     * uart_fifo_read 可能从 FIFO 读取数据导致 uart_poll_in 读不到
     */
    if (uart_poll_in(menu_uart_dev, &c) == 0) {
        return (int)c;
    }

    return -1;
}

void menu_putchar(char c)
{
    menu_uart_init();

    if (menu_uart_dev != NULL) {
        uart_poll_out(menu_uart_dev, c);
    }
}

void menu_puts(const char *str)
{
    while (*str) {
        if (*str == '\n') {
            menu_putchar('\r');
        }
        menu_putchar(*str);
        str++;
    }
}

const struct device *menu_get_uart_dev(void)
{
    menu_uart_init();
    return menu_uart_dev;
}

void menu_printf(const char *fmt, ...)
{
    char buf[256];
    va_list args;

    va_start(args, fmt);
    vsnprintf(buf, sizeof(buf), fmt, args);
    va_end(args);

    menu_puts(buf);
}

void menu_show_banner(void)
{
    menu_puts("\n");
    menu_puts("========================================\n");
    menu_puts("  ART-Pi2 TPL (Stage 2) Bootloader\n");
    menu_puts("========================================\n");
    menu_puts("TPL Address:     0x70000000\n");
    menu_puts("Slot0 (App):     0x70040000\n");
    menu_puts("Slot1 (Update):  0x70140000\n");
    menu_puts("Storage:         0x70240000\n");
    menu_puts("========================================\n");
    menu_puts("\n");
}

void menu_show_menu(void)
{
    menu_puts("\n");
    menu_puts("========================================\n");
    menu_puts("           Bootloader Menu\n");
    menu_puts("========================================\n");
    menu_puts("  1. Update SPL (Stage 1)\n");
    menu_puts("  2. Update TPL (self)\n");
    menu_puts("  3. Update Application (Stage 3)\n");
    menu_puts("  4. Boot Application\n");
    menu_puts("========================================\n");
    menu_puts("  Select (1-4): ");
}

menu_option_t menu_wait_selection(uint32_t timeout_ms)
{
    int c;
    uint32_t start_time = k_uptime_get_32();

    while (1) {
        c = menu_getchar();

        if (c >= '1' && c <= '4') {
            /* 回显 */
            menu_putchar((char)c);
            menu_putchar('\r');
            menu_putchar('\n');
            return (menu_option_t)c;
        }

        /* 检查超时 */
        if (timeout_ms > 0) {
            if ((k_uptime_get_32() - start_time) >= timeout_ms) {
                return MENU_OPT_INVALID;
            }
        }

        k_yield();
    }
}

bool menu_wait_keypress(uint32_t timeout_ms)
{
    int c;
    uint32_t start_time = k_uptime_get_32();

    while (1) {
        c = menu_getchar();

        if (c >= 0) {
            return true;
        }

        /* 检查超时 */
        if (timeout_ms > 0) {
            if ((k_uptime_get_32() - start_time) >= timeout_ms) {
                return false;
            }
        }

        k_sleep(K_MSEC(10));
    }
}

void menu_process_selection(menu_option_t opt)
{
    switch (opt) {
    case MENU_OPT_UPDATE_SPL:
        menu_puts("Starting SPL update...\n");
        /* update_spl.c 中的函数 */
        {
            extern int update_spl_start(void);
            if (update_spl_start() == 0) {
                menu_puts("SPL update complete. Rebooting...\n");
            } else {
                menu_puts("SPL update failed!\n");
            }
        }
        break;

    case MENU_OPT_UPDATE_TPL:
        menu_puts("Starting TPL update...\n");
        {
            extern int update_tpl_start(void);
            if (update_tpl_start() == 0) {
                menu_puts("TPL update complete. Rebooting...\n");
            } else {
                menu_puts("TPL update failed!\n");
            }
        }
        break;

    case MENU_OPT_UPDATE_APP:
        menu_puts("Starting application update...\n");
        {
            extern int update_app_start(void);
            if (update_app_start() == 0) {
                menu_puts("Application update complete. Rebooting...\n");
            } else {
                menu_puts("Application update failed!\n");
            }
        }
        break;

    case MENU_OPT_BOOT_APP:
        menu_puts("Booting application...\n");
        {
            extern void boot_app(void);
            boot_app();
        }
        break;

    default:
        break;
    }
}
```
